# ioam3358 register map
Registers from a debugger description file.
Registers are 32-bit, access not given, no defined reset value unless marked. A register's access mark holds for its fields unless they carry their own. Addresses are absolute; registers are grouped by the start of their names; lines under a group give offsets from that group; [hi:lo] are bit positions; {n}, {i} and the like mark numbered series; 'fields as' and 'values as' point back to an identical list; <NAME> marks a mode.

## PRU0
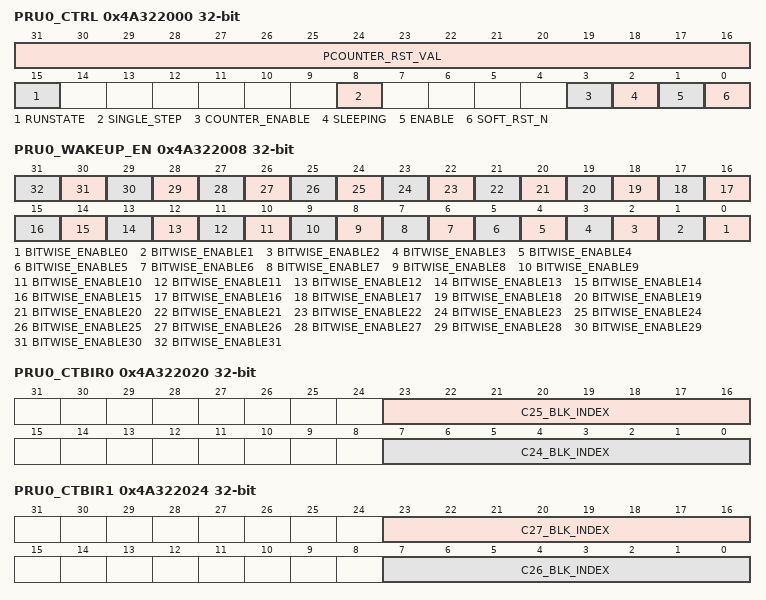
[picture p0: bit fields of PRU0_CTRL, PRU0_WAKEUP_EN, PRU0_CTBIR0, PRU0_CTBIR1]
0x4A322000 PRU0_CTRL
  [31:16] PCOUNTER_RST_VAL, [15] RUNSTATE, [8] SINGLE_STEP, [3] COUNTER_ENABLE, [2] SLEEPING, [1] ENABLE, [0] SOFT_RST_N
0x4A322004 PRU0_STATUS
  [15:0] PCOUNTER
0x4A322008 PRU0_WAKEUP_EN
  [n] BITWISE_ENABLE{n} (n=0..31)
0x4A32200C PRU0_CYCLE
0x4A322010 PRU0_STALL
0x4A322020 PRU0_CTBIR0
  [23:16] C25_BLK_INDEX, [7:0] C24_BLK_INDEX
0x4A322024 PRU0_CTBIR1
  [23:16] C27_BLK_INDEX, [7:0] C26_BLK_INDEX
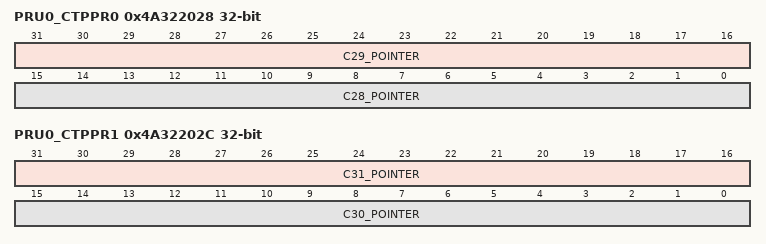
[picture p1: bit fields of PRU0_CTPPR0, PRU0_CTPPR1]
0x4A322028 PRU0_CTPPR0
  [31:16] C29_POINTER, [15:0] C28_POINTER
0x4A32202C PRU0_CTPPR1
  [31:16] C31_POINTER, [15:0] C30_POINTER
{0x4A322400+4i} PRU0_GPREG{i} (i=0..31)
{0x4A322480+4i} PRU0_CT_REG{i} (i=0..31)

## PRU1
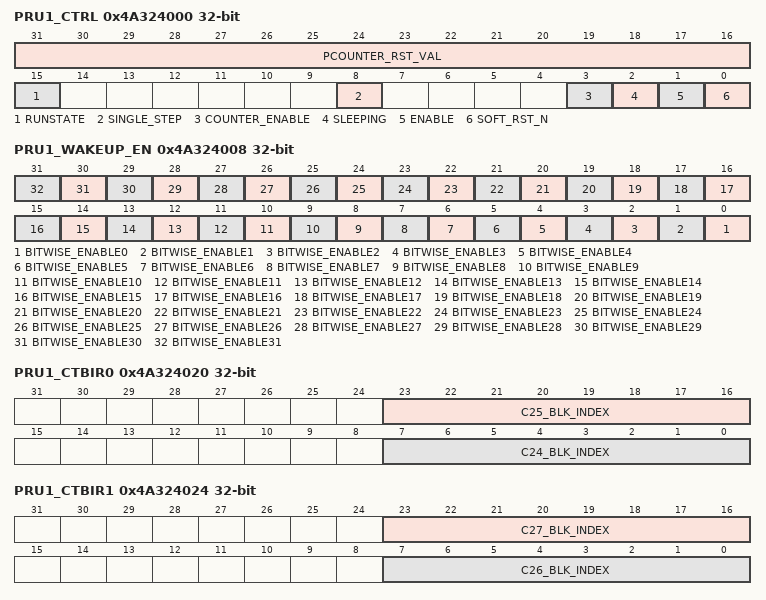
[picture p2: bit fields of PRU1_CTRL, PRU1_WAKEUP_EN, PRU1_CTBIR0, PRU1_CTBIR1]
0x4A324000 PRU1_CTRL
  [31:16] PCOUNTER_RST_VAL, [15] RUNSTATE, [8] SINGLE_STEP, [3] COUNTER_ENABLE, [2] SLEEPING, [1] ENABLE, [0] SOFT_RST_N
0x4A324004 PRU1_STATUS
  [15:0] PCOUNTER
0x4A324008 PRU1_WAKEUP_EN
  [n] BITWISE_ENABLE{n} (n=0..31)
0x4A32400C PRU1_CYCLE
0x4A324010 PRU1_STALL
0x4A324020 PRU1_CTBIR0
  [23:16] C25_BLK_INDEX, [7:0] C24_BLK_INDEX
0x4A324024 PRU1_CTBIR1
  [23:16] C27_BLK_INDEX, [7:0] C26_BLK_INDEX
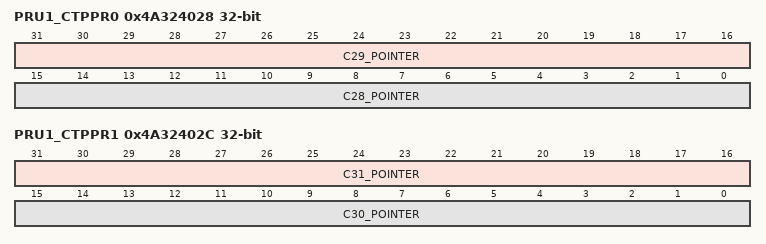
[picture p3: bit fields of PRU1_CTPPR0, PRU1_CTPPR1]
0x4A324028 PRU1_CTPPR0
  [31:16] C29_POINTER, [15:0] C28_POINTER
0x4A32402C PRU1_CTPPR1
  [31:16] C31_POINTER, [15:0] C30_POINTER
{0x4A324400+4i} PRU1_GPREG{i} (i=0..31)
{0x4A324480+4i} PRU1_CT_REG{i} (i=0..31)

## INTC
0x48200000 INTC_REVISION
  [7:0] REV
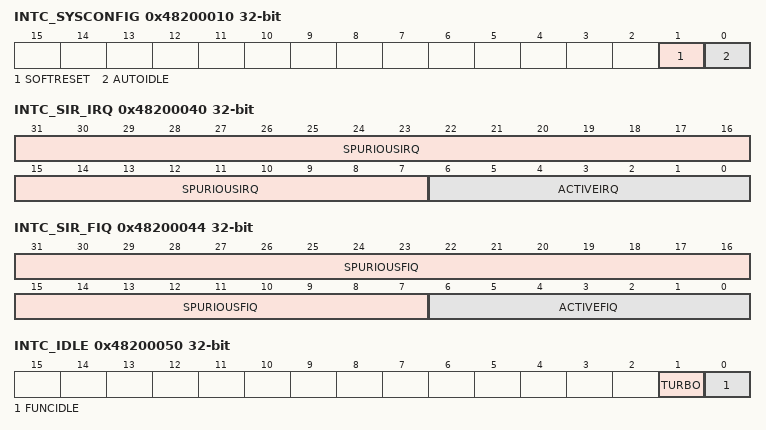
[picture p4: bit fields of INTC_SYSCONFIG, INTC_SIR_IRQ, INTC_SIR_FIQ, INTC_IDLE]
0x48200010 INTC_SYSCONFIG
  [1] SOFTRESET, [0] AUTOIDLE
0x48200014 INTC_SYSSTATUS
  [0] RESETDONE
0x48200040 INTC_SIR_IRQ
  [31:7] SPURIOUSIRQ, [6:0] ACTIVEIRQ
0x48200044 INTC_SIR_FIQ
  [31:7] SPURIOUSFIQ, [6:0] ACTIVEFIQ
0x48200048 INTC_CONTROL
0x4820004C INTC_PROTECTION
  [0] PROTECTION
0x48200050 INTC_IDLE
  [1] TURBO, [0] FUNCIDLE
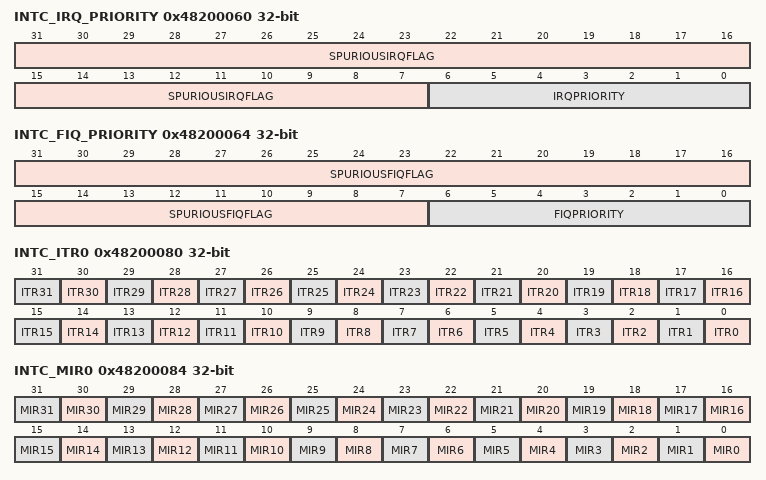
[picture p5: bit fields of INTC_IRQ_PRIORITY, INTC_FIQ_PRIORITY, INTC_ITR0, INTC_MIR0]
0x48200060 INTC_IRQ_PRIORITY
  [31:7] SPURIOUSIRQFLAG, [6:0] IRQPRIORITY
0x48200064 INTC_FIQ_PRIORITY
  [31:7] SPURIOUSFIQFLAG, [6:0] FIQPRIORITY
0x48200068 INTC_THRESHOLD
  [7:0] PRIORITYTHRESHOLD
0x48200080 INTC_ITR0
  [n] ITR{n} (n=0..31)
0x48200084 INTC_MIR0
  [n] MIR{n} (n=0..31)
{0x48200088+0x20*i} INTC_MIR_CLEAR{i} (i=0..3)
{0x4820008C+0x20*i} INTC_MIR_SET{i} (i=0..3)
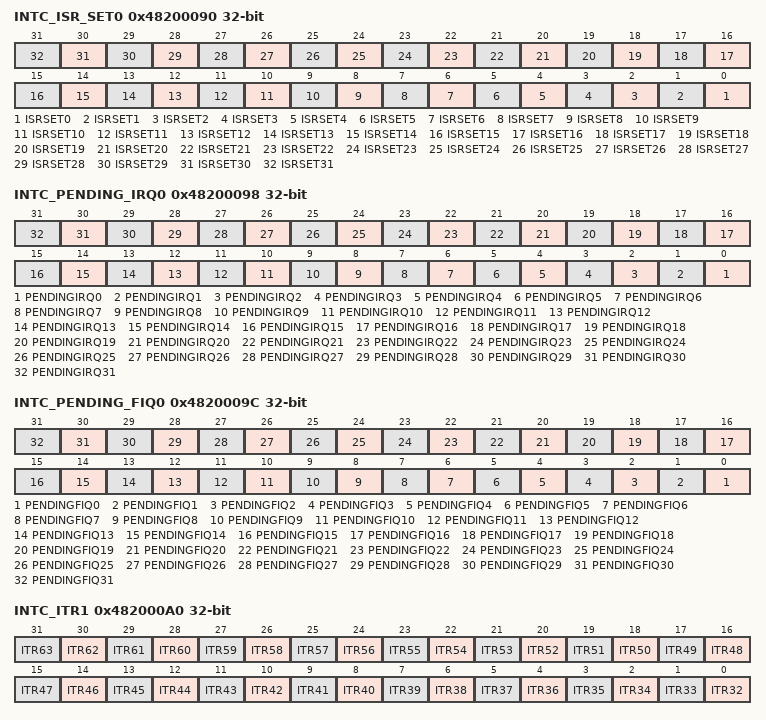
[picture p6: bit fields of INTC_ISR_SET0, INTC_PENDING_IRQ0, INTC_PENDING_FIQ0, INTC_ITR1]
0x48200090 INTC_ISR_SET0
  [n] ISRSET{n} (n=0..31)
{0x48200094+0x20*i} INTC_ISR_CLEAR{i} (i=0..3)
0x48200098 INTC_PENDING_IRQ0
  [n] PENDINGIRQ{n} (n=0..31)
0x4820009C INTC_PENDING_FIQ0
  [n] PENDINGFIQ{n} (n=0..31)
0x482000A0 INTC_ITR1
  [n-32] ITR{n} (n=32..63)
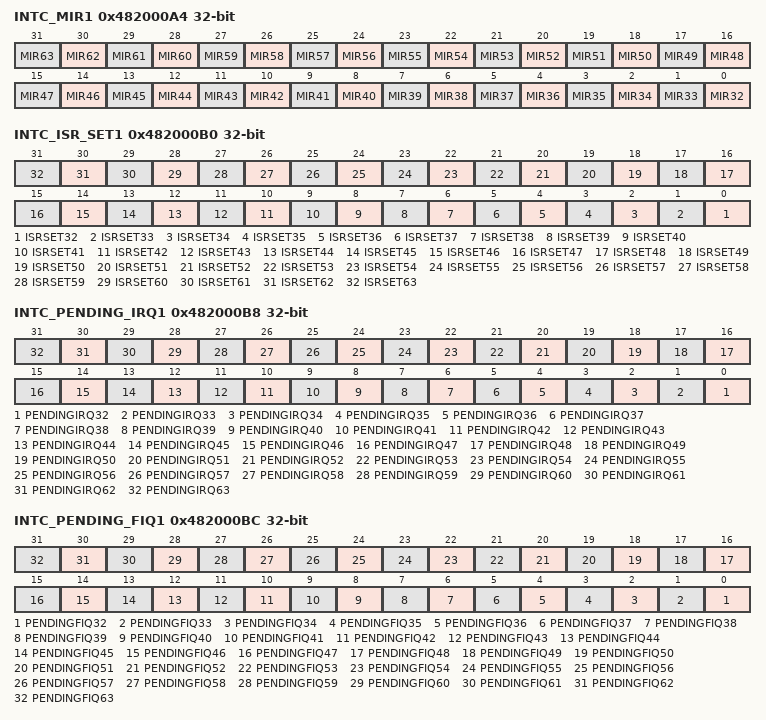
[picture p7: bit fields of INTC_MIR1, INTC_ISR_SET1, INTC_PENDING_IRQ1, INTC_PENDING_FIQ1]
0x482000A4 INTC_MIR1
  [n-32] MIR{n} (n=32..63)
0x482000B0 INTC_ISR_SET1
  [n-32] ISRSET{n} (n=32..63)
0x482000B8 INTC_PENDING_IRQ1
  [n-32] PENDINGIRQ{n} (n=32..63)
0x482000BC INTC_PENDING_FIQ1
  [n-32] PENDINGFIQ{n} (n=32..63)
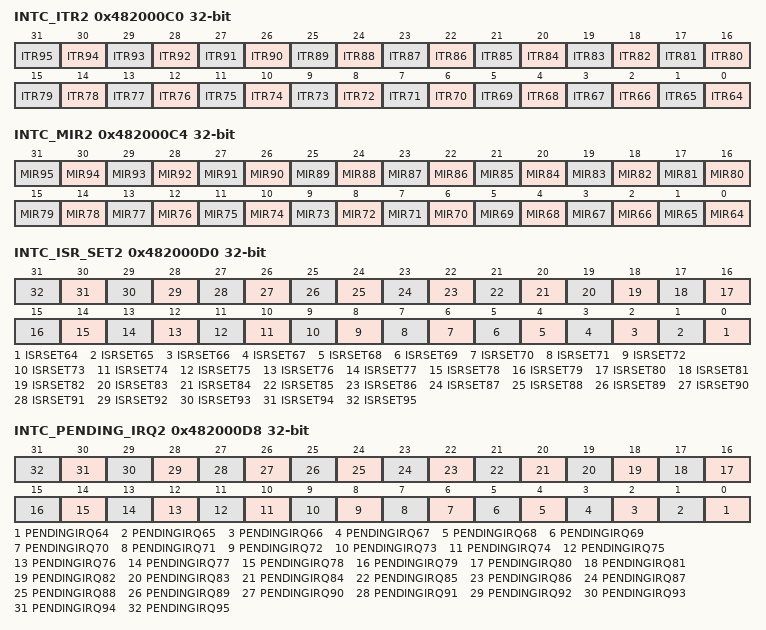
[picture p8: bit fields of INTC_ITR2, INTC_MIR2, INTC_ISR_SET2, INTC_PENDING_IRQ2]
0x482000C0 INTC_ITR2
  [n-64] ITR{n} (n=64..95)
0x482000C4 INTC_MIR2
  [n-64] MIR{n} (n=64..95)
0x482000D0 INTC_ISR_SET2
  [n-64] ISRSET{n} (n=64..95)
0x482000D8 INTC_PENDING_IRQ2
  [n-64] PENDINGIRQ{n} (n=64..95)
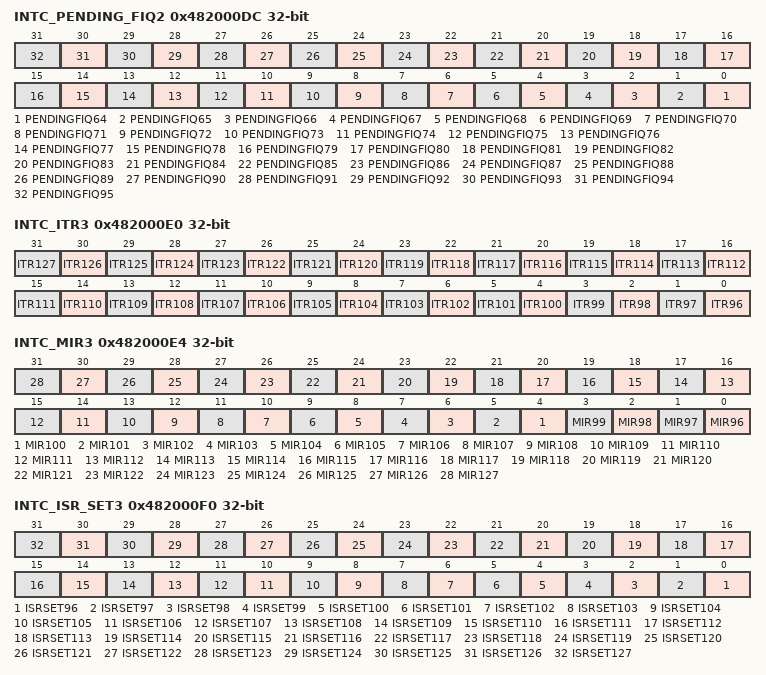
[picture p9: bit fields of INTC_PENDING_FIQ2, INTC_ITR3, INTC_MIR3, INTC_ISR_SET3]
0x482000DC INTC_PENDING_FIQ2
  [n-64] PENDINGFIQ{n} (n=64..95)
0x482000E0 INTC_ITR3
  [n-96] ITR{n} (n=96..127)
0x482000E4 INTC_MIR3
  [n-96] MIR{n} (n=96..127)
0x482000F0 INTC_ISR_SET3
  [n-96] ISRSET{n} (n=96..127)
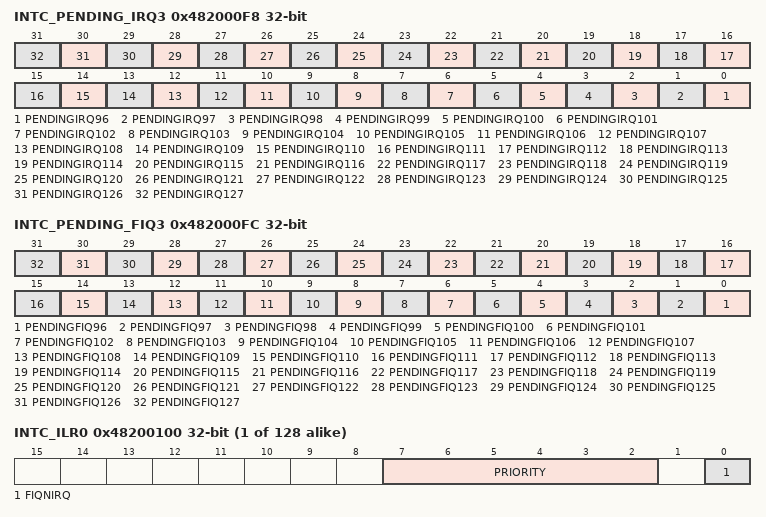
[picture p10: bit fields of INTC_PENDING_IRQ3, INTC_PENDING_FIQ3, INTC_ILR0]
0x482000F8 INTC_PENDING_IRQ3
  [n-96] PENDINGIRQ{n} (n=96..127)
0x482000FC INTC_PENDING_FIQ3
  [n-96] PENDINGFIQ{n} (n=96..127)
{0x48200100+4i} INTC_ILR{i} (i=0..127)
  [7:2] PRIORITY, [0] FIQNIRQ
